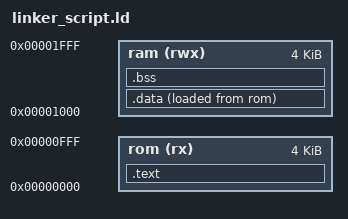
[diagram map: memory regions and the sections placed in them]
MEMORY
{
  rom (rx)  : ORIGIN = 0x0000, LENGTH = 0x1000
  ram (rwx) : ORIGIN = 0x1000, LENGTH = 0x1000
}

SECTIONS
{
  .text :
  {
    . = ALIGN(4);
    _stext = .;
    *(.text .text.*)
    *(.rodata .rodata.*)
    *(.srodata .srodata.*)
    . = ALIGN(4);
    _etext = .;
  } > rom

  .data :
  {
    . = ALIGN(4);
    _sdata = .;
    *(.data .data.*)
    *(.sdata .sdata.*)
    . = ALIGN(4);
    _edata = .;
  } > ram AT> rom

  .bss :
  {
    . = ALIGN(4);
    _sbss = .;
    *(.bss .bss.*)
    *(COMMON)
    . = ALIGN(4);
    _ebss = .;
  } > ram
}
